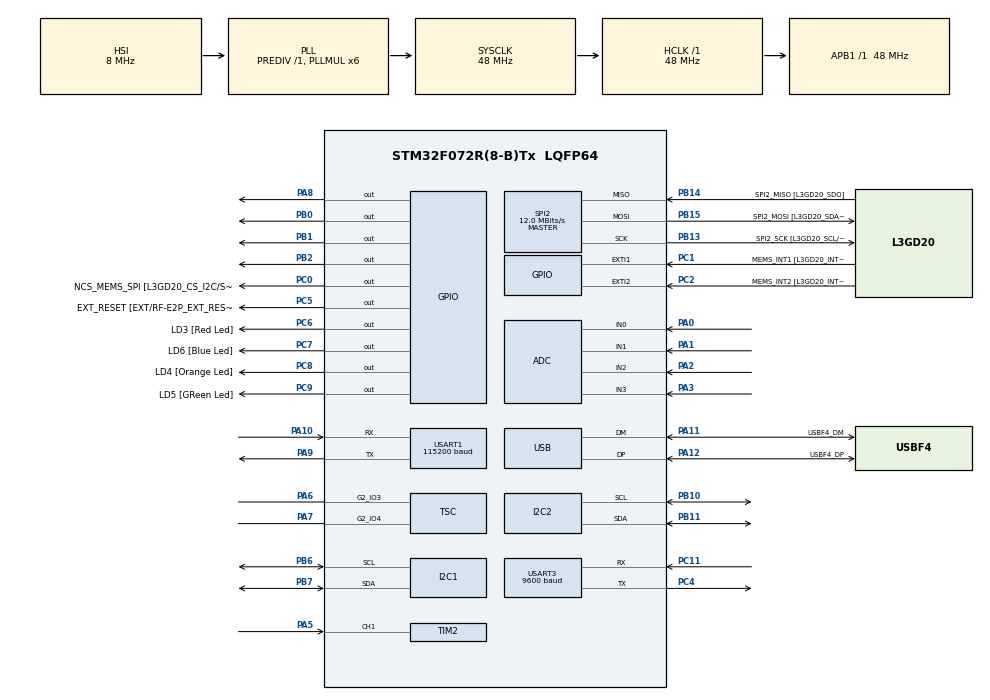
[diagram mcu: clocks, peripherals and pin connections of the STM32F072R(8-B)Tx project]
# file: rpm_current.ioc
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ADC.ContinuousConvMode=DISABLE
ADC.DiscontinuousConvMode=ENABLE
ADC.SamplingTime=ADC_SAMPLETIME_239CYCLES_5
I2C2.Timing=0x20303E5D
Mcu.Family=STM32F0
Mcu.Name=STM32F072R(8-B)Tx
Mcu.Package=LQFP64
NVIC.TIM2_IRQn=true\:0\:0\:false\:false\:true\:true\:true\:true
NVIC.USART1_IRQn=true\:0\:0\:false\:false\:true\:true\:true\:true
PA0.Mode=IN0
PA0.Signal=ADC_IN0
PA1.Mode=IN1
PA1.Signal=ADC_IN1
PA10.Mode=Asynchronous
PA10.Signal=USART1_RX
PA11.GPIO_Label=USBF4_DM
PA11.Mode=Device
PA11.Signal=USB_DM
PA12.GPIO_Label=USBF4_DP
PA12.Mode=Device
PA12.Signal=USB_DP
PA13.GPIO_Label=SWDIO
PA13.Mode=Serial_Wire
PA13.Signal=SYS_SWDIO
PA14.GPIO_Label=SWCLK
PA14.Mode=Serial_Wire
PA14.Signal=SYS_SWCLK
PA2.Mode=IN2
PA2.Signal=ADC_IN2
PA3.Mode=IN3
PA3.Signal=ADC_IN3
PA5.Signal=S_TIM2_CH1_ETR
PA6.Mode=G2_IO3-Channel
PA6.Signal=TSC_G2_IO3
PA7.Mode=G2_IO4-Sampling
PA7.Signal=TSC_G2_IO4
PA8.Signal=GPIO_Output
PA9.Mode=Asynchronous
PA9.Signal=USART1_TX
PB0.Signal=GPIO_Output
PB1.Signal=GPIO_Output
PB10.Mode=I2C
PB10.Signal=I2C2_SCL
PB11.Mode=I2C
PB11.Signal=I2C2_SDA
PB13.GPIO_Label=SPI2_SCK [L3GD20_SCL/SPC]
PB13.Mode=Full_Duplex_Master
PB13.Signal=SPI2_SCK
PB14.GPIO_Label=SPI2_MISO [L3GD20_SDO]
PB14.Mode=Full_Duplex_Master
PB14.Signal=SPI2_MISO
PB15.GPIO_Label=SPI2_MOSI [L3GD20_SDA/SDI]
PB15.Mode=Full_Duplex_Master
PB15.Signal=SPI2_MOSI
PB2.Signal=GPIO_Output
PB6.Mode=I2C
PB6.Signal=I2C1_SCL
PB7.Mode=I2C
PB7.Signal=I2C1_SDA
PC0.GPIO_Label=NCS_MEMS_SPI [L3GD20_CS_I2C/SPI]
PC0.Signal=GPIO_Output
PC1.GPIO_Label=MEMS_INT1 [L3GD20_INT1]
PC1.GPIO_ModeDefaultEXTI=GPIO_MODE_EVT_RISING
PC1.Signal=GPXTI1
PC11.Mode=Asynchronous
PC11.Signal=USART3_RX
PC2.GPIO_Label=MEMS_INT2 [L3GD20_INT2]
PC2.GPIO_ModeDefaultEXTI=GPIO_MODE_EVT_RISING
PC2.Signal=GPXTI2
PC4.Mode=Asynchronous
PC4.Signal=USART3_TX
PC5.GPIO_Label=EXT_RESET [EXT/RF-E2P_EXT_RESET]
PC5.Signal=GPIO_Output
PC6.GPIO_Label=LD3 [Red Led]
PC6.Signal=GPIO_Output
PC7.GPIO_Label=LD6 [Blue Led]
PC7.Signal=GPIO_Output
PC8.GPIO_Label=LD4 [Orange Led]
PC8.Signal=GPIO_Output
PC9.GPIO_Label=LD5 [GReen Led]
PC9.Signal=GPIO_Output
ProjectManager.HeapSize=0x200
ProjectManager.StackSize=0x400
ProjectManager.TargetToolchain=STM32CubeIDE
RCC.AHBFreq_Value=48000000
RCC.APB1Freq_Value=48000000
RCC.APB1TimFreq_Value=48000000
RCC.HCLKFreq_Value=48000000
RCC.PLLMUL=RCC_PLL_MUL6
RCC.SYSCLKFreq_VALUE=48000000
RCC.SYSCLKSource=RCC_SYSCLKSOURCE_PLLCLK
SH.S_TIM2_CH1_ETR.0=TIM2_CH1,Input_Capture1_from_TI1
SPI2.BaudRatePrescaler=SPI_BAUDRATEPRESCALER_4
SPI2.CalculateBaudRate=12.0 MBits/s
SPI2.Direction=SPI_DIRECTION_2LINES
SPI2.Mode=SPI_MODE_MASTER
SPI2.VirtualType=VM_MASTER
TIM2.Channel-Input_Capture1_from_TI1=TIM_CHANNEL_1
TIM2.Prescaler=48-1
USART1.BaudRate=115200
USART1.DMADisableonRxErrorParam=ADVFEATURE_DMA_DISABLEONRXERROR
USART1.OverrunDisableParam=ADVFEATURE_OVERRUN_DISABLE
USART1.SwapParam=ADVFEATURE_SWAP_ENABLE
USART1.VirtualMode-Asynchronous=VM_ASYNC
USART3.BaudRate=9600
USART3.SwapParam=ADVFEATURE_SWAP_DISABLE
USART3.VirtualMode-Asynchronous=VM_ASYNC
USB.phy_itface=PCD_PHY_EMBEDDED
USB.speed=PCD_SPEED_FULL
board=STM32F072B-DISCO

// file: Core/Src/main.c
/* USER CODE BEGIN Header */
/**
  ******************************************************************************
  * @file           : main.c
  * @brief          : Main program body
  ******************************************************************************
  * @attention
  *
  * Copyright (c) 2023 STMicroelectronics.
  * All rights reserved.
  *
  * This software is licensed under terms that can be found in the LICENSE file
  * in the root directory of this software component.
  * If no LICENSE file comes with this software, it is provided AS-IS.
  *
  ******************************************************************************
  */
/* USER CODE END Header */
#include "main.h"
#include "adc.h"
#include "i2c.h"
#include "spi.h"
#include "tim.h"
#include "tsc.h"
#include "usart.h"
#include "usb.h"
#include "gpio.h"

/* USER CODE BEGIN Includes */
#include "my_code.h"
/* USER CODE END Includes */

/* USER CODE BEGIN PV */
/*
uint32_t IC_Val1 = 0;
uint32_t IC_Val2 = 0;
uint32_t Difference = 0;
int Is_First_Captured = 0;

float Frequency = 0;
float rpm = 0;
uint16_t readValue;
float sensitivity = 0.001; // 0.1 for 20A Model
float rawVoltage;
float current;
*/

/* USER CODE END PV */

void SystemClock_Config(void);

int main(void)
{

  /* MCU Configuration--------------------------------------------------------*/

  /* Reset of all peripherals, Initializes the Flash interface and the Systick. */
  HAL_Init();

  /* Configure the system clock */
  SystemClock_Config();

  /* Initialize all configured peripherals */
  MX_GPIO_Init();
  MX_SPI2_Init();
  MX_TSC_Init();
  MX_USB_PCD_Init();
  MX_ADC_Init();
  MX_TIM2_Init();
  MX_USART1_UART_Init();
  MX_USART3_UART_Init();
  MX_I2C1_Init();
  MX_I2C2_Init();
  /* USER CODE BEGIN 2 */

  //I am moving this into setup at some point
  HAL_TIM_IC_Start_IT(&htim2, TIM_CHANNEL_1);

  setup();

  /* USER CODE END 2 */

  /* Infinite loop */
  /* USER CODE BEGIN WHILE */
  while (1)
  {

	  loop();
    /* USER CODE END WHILE */

  }
}

void SystemClock_Config(void)
{
  RCC_OscInitTypeDef RCC_OscInitStruct = {0};
  RCC_ClkInitTypeDef RCC_ClkInitStruct = {0};
  RCC_PeriphCLKInitTypeDef PeriphClkInit = {0};

  /** Initializes the RCC Oscillators according to the specified parameters
  * in the RCC_OscInitTypeDef structure.
  */
  RCC_OscInitStruct.OscillatorType = RCC_OSCILLATORTYPE_HSI|RCC_OSCILLATORTYPE_HSI14
                              |RCC_OSCILLATORTYPE_HSI48;
  RCC_OscInitStruct.HSIState = RCC_HSI_ON;
  RCC_OscInitStruct.HSI48State = RCC_HSI48_ON;
  RCC_OscInitStruct.HSI14State = RCC_HSI14_ON;
  RCC_OscInitStruct.HSICalibrationValue = RCC_HSICALIBRATION_DEFAULT;
  RCC_OscInitStruct.HSI14CalibrationValue = 16;
  RCC_OscInitStruct.PLL.PLLState = RCC_PLL_ON;
  RCC_OscInitStruct.PLL.PLLSource = RCC_PLLSOURCE_HSI;
  RCC_OscInitStruct.PLL.PLLMUL = RCC_PLL_MUL6;
  RCC_OscInitStruct.PLL.PREDIV = RCC_PREDIV_DIV1;
  if (HAL_RCC_OscConfig(&RCC_OscInitStruct) != HAL_OK)
  {
    Error_Handler();
  }

  /** Initializes the CPU, AHB and APB buses clocks
  */
  RCC_ClkInitStruct.ClockType = RCC_CLOCKTYPE_HCLK|RCC_CLOCKTYPE_SYSCLK
                              |RCC_CLOCKTYPE_PCLK1;
  RCC_ClkInitStruct.SYSCLKSource = RCC_SYSCLKSOURCE_PLLCLK;
  RCC_ClkInitStruct.AHBCLKDivider = RCC_SYSCLK_DIV1;
  RCC_ClkInitStruct.APB1CLKDivider = RCC_HCLK_DIV1;

  if (HAL_RCC_ClockConfig(&RCC_ClkInitStruct, FLASH_LATENCY_1) != HAL_OK)
  {
    Error_Handler();
  }
  PeriphClkInit.PeriphClockSelection = RCC_PERIPHCLK_USB|RCC_PERIPHCLK_USART1
                              |RCC_PERIPHCLK_I2C1;
  PeriphClkInit.Usart1ClockSelection = RCC_USART1CLKSOURCE_PCLK1;
  PeriphClkInit.I2c1ClockSelection = RCC_I2C1CLKSOURCE_HSI;
  PeriphClkInit.UsbClockSelection = RCC_USBCLKSOURCE_HSI48;

  if (HAL_RCCEx_PeriphCLKConfig(&PeriphClkInit) != HAL_OK)
  {
    Error_Handler();
  }
}

void Error_Handler(void)
{
  __disable_irq();
  while (1)
  {
  }
}
